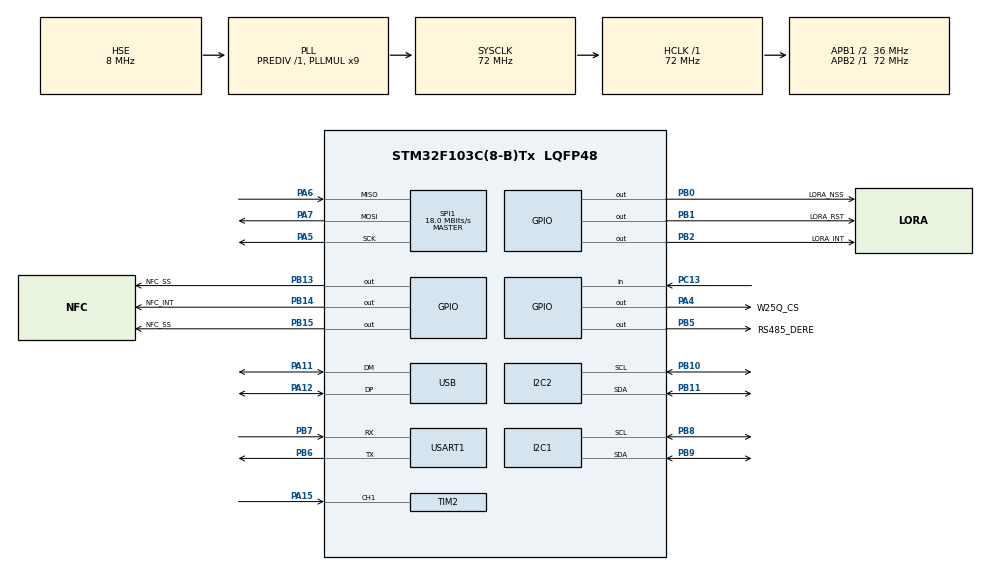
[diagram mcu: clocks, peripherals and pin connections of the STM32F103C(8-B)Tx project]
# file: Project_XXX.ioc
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FREERTOS.Tasks01=defaultTask,0,128,StartDefaultTask,Default,NULL,Dynamic,NULL,NULL
FREERTOS.configUSE_NEWLIB_REENTRANT=1
Mcu.Family=STM32F1
Mcu.Name=STM32F103C(8-B)Tx
Mcu.Package=LQFP48
NVIC.PriorityGroup=NVIC_PRIORITYGROUP_4
NVIC.TIM4_IRQn=true\:15\:0\:false\:false\:true\:false\:false\:true\:true
NVIC.TimeBase=TIM4_IRQn
NVIC.TimeBaseIP=TIM4
NVIC.USB_LP_CAN1_RX0_IRQn=true\:5\:0\:false\:false\:true\:true\:false\:true\:true
PA11.Mode=Device
PA11.Signal=USB_DM
PA12.Mode=Device
PA12.Signal=USB_DP
PA13.Mode=Serial_Wire
PA13.Signal=SYS_JTMS-SWDIO
PA14.Mode=Serial_Wire
PA14.Signal=SYS_JTCK-SWCLK
PA15.Signal=S_TIM2_CH1_ETR
PA4.GPIO_Label=W25Q_CS
PA4.Signal=GPIO_Output
PA5.Mode=Full_Duplex_Master
PA5.Signal=SPI1_SCK
PA6.Mode=Full_Duplex_Master
PA6.Signal=SPI1_MISO
PA7.Mode=Full_Duplex_Master
PA7.Signal=SPI1_MOSI
PB0.GPIO_Label=LORA_NSS
PB0.Signal=GPIO_Output
PB1.GPIO_Label=LORA_RST
PB1.Signal=GPIO_Output
PB10.Mode=I2C
PB10.Signal=I2C2_SCL
PB11.Mode=I2C
PB11.Signal=I2C2_SDA
PB13.GPIO_Label=NFC_SS
PB13.Signal=GPIO_Output
PB14.GPIO_Label=NFC_INT
PB14.Signal=GPIO_Output
PB15.GPIO_Label=NFC_SS
PB15.Signal=GPIO_Output
PB2.GPIO_Label=LORA_INT
PB2.Signal=GPIO_Output
PB5.GPIO_Label=RS485_DERE
PB5.Signal=GPIO_Output
PB6.Mode=Asynchronous
PB6.Signal=USART1_TX
PB7.Mode=Asynchronous
PB7.Signal=USART1_RX
PB8.Mode=I2C
PB8.Signal=I2C1_SCL
PB9.Mode=I2C
PB9.Signal=I2C1_SDA
PC13-TAMPER-RTC.Signal=GPIO_Input
PD0-OSC_IN.Mode=HSE-External-Oscillator
PD0-OSC_IN.Signal=RCC_OSC_IN
PD1-OSC_OUT.Mode=HSE-External-Oscillator
PD1-OSC_OUT.Signal=RCC_OSC_OUT
ProjectManager.HeapSize=0x200
ProjectManager.StackSize=0x400
ProjectManager.TargetToolchain=STM32CubeIDE
RCC.ADCPresc=RCC_ADCPCLK2_DIV6
RCC.AHBFreq_Value=72000000
RCC.APB1CLKDivider=RCC_HCLK_DIV2
RCC.APB1Freq_Value=36000000
RCC.APB1TimFreq_Value=72000000
RCC.APB2Freq_Value=72000000
RCC.APB2TimFreq_Value=72000000
RCC.HCLKFreq_Value=72000000
RCC.PLLMUL=RCC_PLL_MUL9
RCC.PLLSourceVirtual=RCC_PLLSOURCE_HSE
RCC.SYSCLKFreq_VALUE=72000000
RCC.SYSCLKSource=RCC_SYSCLKSOURCE_PLLCLK
RCC.USBFreq_Value=48000000
RCC.USBPrescaler=RCC_USBCLKSOURCE_PLL_DIV1_5
SH.S_TIM2_CH1_ETR.0=TIM2_CH1,PWM_Input_1
SPI1.BaudRatePrescaler=SPI_BAUDRATEPRESCALER_4
SPI1.CalculateBaudRate=18.0 MBits/s
SPI1.Direction=SPI_DIRECTION_2LINES
SPI1.Mode=SPI_MODE_MASTER
SPI1.VirtualType=VM_MASTER
USART1.VirtualMode=VM_ASYNC
USB_DEVICE.CLASS_NAME_FS=CDC
USB_DEVICE.VirtualMode=Cdc
USB_DEVICE.VirtualModeFS=Cdc_FS
VP_FREERTOS_VS_CMSIS_V1.Mode=CMSIS_V1
VP_SYS_VS_tim4.Mode=TIM4
VP_USB_DEVICE_VS_USB_DEVICE_CDC_FS.Mode=CDC_FS
board=custom

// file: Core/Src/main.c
/* USER CODE BEGIN Header */
/**
  ******************************************************************************
  * @file           : main.c
  * @brief          : Main program body
  ******************************************************************************
  * @attention
  *
  * Copyright (c) 2023 STMicroelectronics.
  * All rights reserved.
  *
  * This software is licensed under terms that can be found in the LICENSE file
  * in the root directory of this software component.
  * If no LICENSE file comes with this software, it is provided AS-IS.
  *
  ******************************************************************************
  */
/* USER CODE END Header */
#include "main.h"
#include "cmsis_os.h"
#include "usb_device.h"

/* USER CODE BEGIN Includes */
#include "pn532.h"
/* USER CODE END Includes */

I2C_HandleTypeDef hi2c1;
I2C_HandleTypeDef hi2c2;

SPI_HandleTypeDef hspi1;

TIM_HandleTypeDef htim2;

UART_HandleTypeDef huart1;

osThreadId defaultTaskHandle;

void SystemClock_Config(void);
static void MX_GPIO_Init(void);
static void MX_SPI1_Init(void);
static void MX_I2C2_Init(void);
static void MX_USART1_UART_Init(void);
static void MX_TIM2_Init(void);
static void MX_I2C1_Init(void);
void StartDefaultTask(void const * argument);

int main(void)
{

  /* MCU Configuration--------------------------------------------------------*/

  /* Reset of all peripherals, Initializes the Flash interface and the Systick. */
  HAL_Init();

  /* Configure the system clock */
  SystemClock_Config();

  /* Initialize all configured peripherals */
  MX_GPIO_Init();
  MX_SPI1_Init();
  MX_I2C2_Init();
  MX_USART1_UART_Init();
  MX_TIM2_Init();
  MX_I2C1_Init();

  /* Create the thread(s) */
  /* definition and creation of defaultTask */
  osThreadDef(defaultTask, StartDefaultTask, osPriorityNormal, 0, 128);
  defaultTaskHandle = osThreadCreate(osThread(defaultTask), NULL);

  /* Start scheduler */
  osKernelStart();

  /* We should never get here as control is now taken by the scheduler */
  /* Infinite loop */
  while (1)
  {
  }
}

void SystemClock_Config(void)
{
  RCC_OscInitTypeDef RCC_OscInitStruct = {0};
  RCC_ClkInitTypeDef RCC_ClkInitStruct = {0};
  RCC_PeriphCLKInitTypeDef PeriphClkInit = {0};

  /** Initializes the RCC Oscillators according to the specified parameters
  * in the RCC_OscInitTypeDef structure.
  */
  RCC_OscInitStruct.OscillatorType = RCC_OSCILLATORTYPE_HSE;
  RCC_OscInitStruct.HSEState = RCC_HSE_ON;
  RCC_OscInitStruct.HSEPredivValue = RCC_HSE_PREDIV_DIV1;
  RCC_OscInitStruct.HSIState = RCC_HSI_ON;
  RCC_OscInitStruct.PLL.PLLState = RCC_PLL_ON;
  RCC_OscInitStruct.PLL.PLLSource = RCC_PLLSOURCE_HSE;
  RCC_OscInitStruct.PLL.PLLMUL = RCC_PLL_MUL9;
  if (HAL_RCC_OscConfig(&RCC_OscInitStruct) != HAL_OK)
  {
    Error_Handler();
  }

  /** Initializes the CPU, AHB and APB buses clocks
  */
  RCC_ClkInitStruct.ClockType = RCC_CLOCKTYPE_HCLK|RCC_CLOCKTYPE_SYSCLK
                              |RCC_CLOCKTYPE_PCLK1|RCC_CLOCKTYPE_PCLK2;
  RCC_ClkInitStruct.SYSCLKSource = RCC_SYSCLKSOURCE_PLLCLK;
  RCC_ClkInitStruct.AHBCLKDivider = RCC_SYSCLK_DIV1;
  RCC_ClkInitStruct.APB1CLKDivider = RCC_HCLK_DIV2;
  RCC_ClkInitStruct.APB2CLKDivider = RCC_HCLK_DIV1;

  if (HAL_RCC_ClockConfig(&RCC_ClkInitStruct, FLASH_LATENCY_2) != HAL_OK)
  {
    Error_Handler();
  }
  PeriphClkInit.PeriphClockSelection = RCC_PERIPHCLK_USB;
  PeriphClkInit.UsbClockSelection = RCC_USBCLKSOURCE_PLL_DIV1_5;
  if (HAL_RCCEx_PeriphCLKConfig(&PeriphClkInit) != HAL_OK)
  {
    Error_Handler();
  }
}

static void MX_I2C1_Init(void)
{

  hi2c1.Instance = I2C1;
  hi2c1.Init.ClockSpeed = 100000;
  hi2c1.Init.DutyCycle = I2C_DUTYCYCLE_2;
  hi2c1.Init.OwnAddress1 = 0;
  hi2c1.Init.AddressingMode = I2C_ADDRESSINGMODE_7BIT;
  hi2c1.Init.DualAddressMode = I2C_DUALADDRESS_DISABLE;
  hi2c1.Init.OwnAddress2 = 0;
  hi2c1.Init.GeneralCallMode = I2C_GENERALCALL_DISABLE;
  hi2c1.Init.NoStretchMode = I2C_NOSTRETCH_DISABLE;
  if (HAL_I2C_Init(&hi2c1) != HAL_OK)
  {
    Error_Handler();
  }

}

static void MX_I2C2_Init(void)
{

  hi2c2.Instance = I2C2;
  hi2c2.Init.ClockSpeed = 100000;
  hi2c2.Init.DutyCycle = I2C_DUTYCYCLE_2;
  hi2c2.Init.OwnAddress1 = 0;
  hi2c2.Init.AddressingMode = I2C_ADDRESSINGMODE_7BIT;
  hi2c2.Init.DualAddressMode = I2C_DUALADDRESS_DISABLE;
  hi2c2.Init.OwnAddress2 = 0;
  hi2c2.Init.GeneralCallMode = I2C_GENERALCALL_DISABLE;
  hi2c2.Init.NoStretchMode = I2C_NOSTRETCH_DISABLE;
  if (HAL_I2C_Init(&hi2c2) != HAL_OK)
  {
    Error_Handler();
  }

}

static void MX_SPI1_Init(void)
{

  /* SPI1 parameter configuration*/
  hspi1.Instance = SPI1;
  hspi1.Init.Mode = SPI_MODE_MASTER;
  hspi1.Init.Direction = SPI_DIRECTION_2LINES;
  hspi1.Init.DataSize = SPI_DATASIZE_8BIT;
  hspi1.Init.CLKPolarity = SPI_POLARITY_LOW;
  hspi1.Init.CLKPhase = SPI_PHASE_1EDGE;
  hspi1.Init.NSS = SPI_NSS_SOFT;
  hspi1.Init.BaudRatePrescaler = SPI_BAUDRATEPRESCALER_4;
  hspi1.Init.FirstBit = SPI_FIRSTBIT_MSB;
  hspi1.Init.TIMode = SPI_TIMODE_DISABLE;
  hspi1.Init.CRCCalculation = SPI_CRCCALCULATION_DISABLE;
  hspi1.Init.CRCPolynomial = 10;
  if (HAL_SPI_Init(&hspi1) != HAL_OK)
  {
    Error_Handler();
  }

}

static void MX_TIM2_Init(void)
{

  TIM_SlaveConfigTypeDef sSlaveConfig = {0};
  TIM_IC_InitTypeDef sConfigIC = {0};
  TIM_MasterConfigTypeDef sMasterConfig = {0};

  htim2.Instance = TIM2;
  htim2.Init.Prescaler = 0;
  htim2.Init.CounterMode = TIM_COUNTERMODE_UP;
  htim2.Init.Period = 65535;
  htim2.Init.ClockDivision = TIM_CLOCKDIVISION_DIV1;
  htim2.Init.AutoReloadPreload = TIM_AUTORELOAD_PRELOAD_DISABLE;
  if (HAL_TIM_IC_Init(&htim2) != HAL_OK)
  {
    Error_Handler();
  }
  sSlaveConfig.SlaveMode = TIM_SLAVEMODE_RESET;
  sSlaveConfig.InputTrigger = TIM_TS_TI1FP1;
  sSlaveConfig.TriggerPolarity = TIM_INPUTCHANNELPOLARITY_RISING;
  sSlaveConfig.TriggerPrescaler = TIM_ICPSC_DIV1;
  sSlaveConfig.TriggerFilter = 0;
  if (HAL_TIM_SlaveConfigSynchro(&htim2, &sSlaveConfig) != HAL_OK)
  {
    Error_Handler();
  }
  sConfigIC.ICPolarity = TIM_INPUTCHANNELPOLARITY_RISING;
  sConfigIC.ICSelection = TIM_ICSELECTION_DIRECTTI;
  sConfigIC.ICPrescaler = TIM_ICPSC_DIV1;
  sConfigIC.ICFilter = 0;
  if (HAL_TIM_IC_ConfigChannel(&htim2, &sConfigIC, TIM_CHANNEL_1) != HAL_OK)
  {
    Error_Handler();
  }
  sConfigIC.ICPolarity = TIM_INPUTCHANNELPOLARITY_FALLING;
  sConfigIC.ICSelection = TIM_ICSELECTION_INDIRECTTI;
  if (HAL_TIM_IC_ConfigChannel(&htim2, &sConfigIC, TIM_CHANNEL_2) != HAL_OK)
  {
    Error_Handler();
  }
  sMasterConfig.MasterOutputTrigger = TIM_TRGO_RESET;
  sMasterConfig.MasterSlaveMode = TIM_MASTERSLAVEMODE_DISABLE;
  if (HAL_TIMEx_MasterConfigSynchronization(&htim2, &sMasterConfig) != HAL_OK)
  {
    Error_Handler();
  }

}

static void MX_USART1_UART_Init(void)
{

  huart1.Instance = USART1;
  huart1.Init.BaudRate = 115200;
  huart1.Init.WordLength = UART_WORDLENGTH_8B;
  huart1.Init.StopBits = UART_STOPBITS_1;
  huart1.Init.Parity = UART_PARITY_NONE;
  huart1.Init.Mode = UART_MODE_TX_RX;
  huart1.Init.HwFlowCtl = UART_HWCONTROL_NONE;
  huart1.Init.OverSampling = UART_OVERSAMPLING_16;
  if (HAL_UART_Init(&huart1) != HAL_OK)
  {
    Error_Handler();
  }

}

static void MX_GPIO_Init(void)
{
  GPIO_InitTypeDef GPIO_InitStruct = {0};

  /* GPIO Ports Clock Enable */
  __HAL_RCC_GPIOC_CLK_ENABLE();
  __HAL_RCC_GPIOD_CLK_ENABLE();
  __HAL_RCC_GPIOA_CLK_ENABLE();
  __HAL_RCC_GPIOB_CLK_ENABLE();

  /*Configure GPIO pin Output Level */
  HAL_GPIO_WritePin(W25Q_CS_GPIO_Port, W25Q_CS_Pin, GPIO_PIN_RESET);

  /*Configure GPIO pin Output Level */
  HAL_GPIO_WritePin(GPIOB, LORA_NSS_Pin|LORA_RST_Pin|LORA_INT_Pin|NFC_SS_Pin
                          |NFC_INT_Pin|NFC_SSB15_Pin|RS485_DERE_Pin, GPIO_PIN_RESET);

  /*Configure GPIO pin : PC13 */
  GPIO_InitStruct.Pin = GPIO_PIN_13;
  GPIO_InitStruct.Mode = GPIO_MODE_INPUT;
  GPIO_InitStruct.Pull = GPIO_NOPULL;
  HAL_GPIO_Init(GPIOC, &GPIO_InitStruct);

  /*Configure GPIO pin : W25Q_CS_Pin */
  GPIO_InitStruct.Pin = W25Q_CS_Pin;
  GPIO_InitStruct.Mode = GPIO_MODE_OUTPUT_PP;
  GPIO_InitStruct.Pull = GPIO_NOPULL;
  GPIO_InitStruct.Speed = GPIO_SPEED_FREQ_LOW;
  HAL_GPIO_Init(W25Q_CS_GPIO_Port, &GPIO_InitStruct);

  /*Configure GPIO pins : LORA_NSS_Pin LORA_RST_Pin LORA_INT_Pin NFC_SS_Pin
                           NFC_INT_Pin NFC_SSB15_Pin RS485_DERE_Pin */
  GPIO_InitStruct.Pin = LORA_NSS_Pin|LORA_RST_Pin|LORA_INT_Pin|NFC_SS_Pin
                          |NFC_INT_Pin|NFC_SSB15_Pin|RS485_DERE_Pin;
  GPIO_InitStruct.Mode = GPIO_MODE_OUTPUT_PP;
  GPIO_InitStruct.Pull = GPIO_NOPULL;
  GPIO_InitStruct.Speed = GPIO_SPEED_FREQ_LOW;
  HAL_GPIO_Init(GPIOB, &GPIO_InitStruct);

}

void StartDefaultTask(void const * argument)
{
  /* init code for USB_DEVICE */
  MX_USB_DEVICE_Init();
  for(;;)
  {
    osDelay(1);
  }
}

void HAL_TIM_PeriodElapsedCallback(TIM_HandleTypeDef *htim)
{
  if (htim->Instance == TIM4) {
    HAL_IncTick();
  }
}

void Error_Handler(void)
{
  __disable_irq();
  while (1)
  {
  }
}
